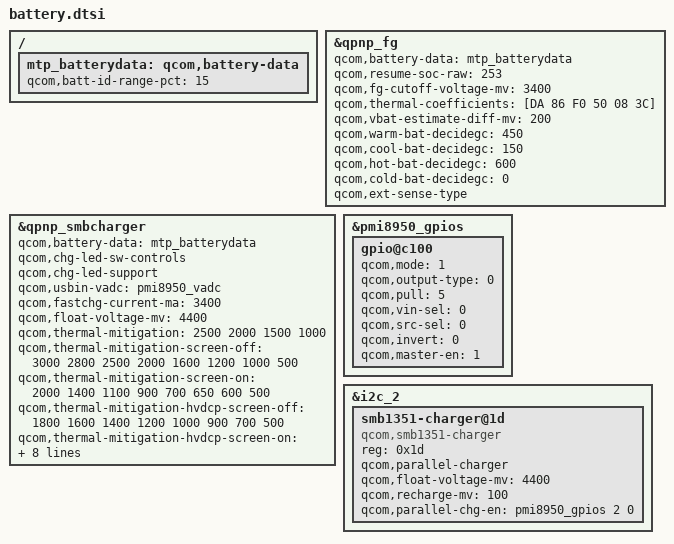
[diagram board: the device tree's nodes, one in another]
/* msm8953-oxygen.dtsi */

/{
	mtp_batterydata: qcom,battery-data {
		qcom,batt-id-range-pct = <15>;
		#include "batterydata/batterydata-d4-sunwoda-5300mAh.dtsi"
		#include "batterydata/batterydata-d4-coslight-5300mAh.dtsi"
	};
};

&qpnp_fg {
	qcom,battery-data = <&mtp_batterydata>;
	qcom,resume-soc-raw = <253>;
	qcom,fg-cutoff-voltage-mv = <3400>;
	qcom,thermal-coefficients = [DA 86 F0 50 08 3C];
	qcom,vbat-estimate-diff-mv = <200>;
	qcom,warm-bat-decidegc = <450>;
	qcom,cool-bat-decidegc = <150>;
	qcom,hot-bat-decidegc  = <600>;
	qcom,cold-bat-decidegc = <0>;
	qcom,ext-sense-type;
};

&qpnp_smbcharger {
	qcom,battery-data = <&mtp_batterydata>;
	qcom,chg-led-sw-controls;
	qcom,chg-led-support;
	qcom,usbin-vadc = <&pmi8950_vadc>;

	qcom,fastchg-current-ma = <3400>;
	qcom,float-voltage-mv = <4400>;
	qcom,thermal-mitigation = <2500 2000 1500 1000>;
	qcom,thermal-mitigation-screen-off = <3000 2800 2500 2000 1600 1200 1000 500>;
	qcom,thermal-mitigation-screen-on = <2000 1400 1100 900 700 650 600 500>;
	qcom,thermal-mitigation-hvdcp-screen-off = <1800 1600 1400 1200 1000 900 700 500>;
	qcom,thermal-mitigation-hvdcp-screen-on = <1200 900 700 600 550 500 500 500>;
	qcom,thermal-fcc-screen-off = <3400 3200 2800 2400 1600 1200 1000 500>;
	qcom,thermal-fcc-screen-on = <1800 1100 1000 900 700 500 300 500>;
	qcom,fastchg-current-comp = <1200>;
	qcom,float-voltage-comp = <16>;
	qcom,override-usb-current;
};

/* NOTE: Needs adaption */
&pmi8950_gpios {
	/* GPIO 2 (CHG_STAT) */
	gpio@c100 {
		qcom,mode = <1>;	/* Digital output */
		qcom,output-type = <0>;	/* CMOS */
		qcom,pull = <5>;	/* No pull */
		qcom,vin-sel = <0>;	/* VIN0 */
		qcom,src-sel = <0>;	/* Constant */
		qcom,invert = <0>;	/* Output low initially */
		qcom,master-en = <1>;	/* GPIO enabled */
		status = "okay";
	};
};

&i2c_2 {
	smb1351-charger@1d {
		compatible = "qcom,smb1351-charger";
		reg = <0x1d>;
		qcom,parallel-charger;
		qcom,float-voltage-mv = <4400>;
		qcom,recharge-mv = <100>;
		qcom,parallel-chg-en = <&pmi8950_gpios 2 0>;
	};
};
